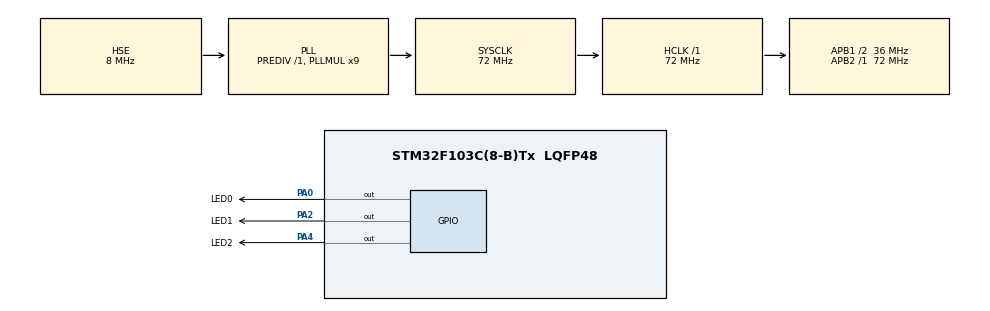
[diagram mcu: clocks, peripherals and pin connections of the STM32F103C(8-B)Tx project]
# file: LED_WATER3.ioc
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Mcu.Family=STM32F1
Mcu.Name=STM32F103C(8-B)Tx
Mcu.Package=LQFP48
NVIC.PriorityGroup=NVIC_PRIORITYGROUP_4
PA0-WKUP.GPIO_Label=LED0
PA0-WKUP.Signal=GPIO_Output
PA13.Mode=Serial_Wire
PA13.Signal=SYS_JTMS-SWDIO
PA14.Mode=Serial_Wire
PA14.Signal=SYS_JTCK-SWCLK
PA2.GPIO_Label=LED1
PA2.Signal=GPIO_Output
PA4.GPIO_Label=LED2
PA4.Signal=GPIO_Output
PD0-OSC_IN.Mode=HSE-External-Oscillator
PD0-OSC_IN.Signal=RCC_OSC_IN
PD1-OSC_OUT.Mode=HSE-External-Oscillator
PD1-OSC_OUT.Signal=RCC_OSC_OUT
ProjectManager.HeapSize=0x200
ProjectManager.StackSize=0x400
ProjectManager.TargetToolchain=STM32CubeIDE
RCC.AHBFreq_Value=72000000
RCC.APB1CLKDivider=RCC_HCLK_DIV2
RCC.APB1Freq_Value=36000000
RCC.APB1TimFreq_Value=72000000
RCC.APB2Freq_Value=72000000
RCC.APB2TimFreq_Value=72000000
RCC.HCLKFreq_Value=72000000
RCC.PLLMUL=RCC_PLL_MUL9
RCC.PLLSourceVirtual=RCC_PLLSOURCE_HSE
RCC.SYSCLKFreq_VALUE=72000000
RCC.SYSCLKSource=RCC_SYSCLKSOURCE_PLLCLK
RCC.USBFreq_Value=72000000
board=custom

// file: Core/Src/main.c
/* USER CODE BEGIN Header */
/**
  ******************************************************************************
  * @file           : main.c
  * @brief          : Main program body
  ******************************************************************************
  * @attention
  *
  * Copyright (c) 2026 STMicroelectronics.
  * All rights reserved.
  *
  * This software is licensed under terms that can be found in the LICENSE file
  * in the root directory of this software component.
  * If no LICENSE file comes with this software, it is provided AS-IS.
  *
  ******************************************************************************
  */
/* USER CODE END Header */
#include "main.h"
#include "gpio.h"

/* USER CODE BEGIN PD */
#define LED_NUM               3U
#define LED_FLOW_INTERVAL_MS  500U
#define LED_LEVEL_ON          GPIO_PIN_SET
#define LED_LEVEL_OFF         GPIO_PIN_RESET
/* USER CODE END PD */

/* USER CODE BEGIN PV */
typedef struct
{
  GPIO_TypeDef *port;
  uint16_t      pin;
} LedDef_t;

static const LedDef_t s_ledTable[LED_NUM] =
{
  { LED0_GPIO_Port, LED0_Pin },
  { LED1_GPIO_Port, LED1_Pin },
  { LED2_GPIO_Port, LED2_Pin },
};

static uint32_t s_lastTick = 0U;
static uint8_t  s_step     = 0U;
/* USER CODE END PV */

void SystemClock_Config(void);
/* USER CODE BEGIN PFP */
static void Led_Write(uint8_t idx, uint8_t on);
static void LedFlow_Init(void);
static void LedFlow_Task(void);
/* USER CODE END PFP */

int main(void)
{

  /* MCU Configuration--------------------------------------------------------*/

  /* Reset of all peripherals, Initializes the Flash interface and the Systick. */
  HAL_Init();

  /* Configure the system clock */
  SystemClock_Config();

  /* Initialize all configured peripherals */
  MX_GPIO_Init();
  /* USER CODE BEGIN 2 */
  LedFlow_Init();
  /* USER CODE END 2 */

  /* Infinite loop */
  while (1)
  {

    /* USER CODE BEGIN 3 */
    LedFlow_Task();
  }
  /* USER CODE END 3 */
}

void SystemClock_Config(void)
{
  RCC_OscInitTypeDef RCC_OscInitStruct = {0};
  RCC_ClkInitTypeDef RCC_ClkInitStruct = {0};

  /** Initializes the RCC Oscillators according to the specified parameters
  * in the RCC_OscInitTypeDef structure.
  */
  RCC_OscInitStruct.OscillatorType = RCC_OSCILLATORTYPE_HSE;
  RCC_OscInitStruct.HSEState = RCC_HSE_ON;
  RCC_OscInitStruct.HSEPredivValue = RCC_HSE_PREDIV_DIV1;
  RCC_OscInitStruct.HSIState = RCC_HSI_ON;
  RCC_OscInitStruct.PLL.PLLState = RCC_PLL_ON;
  RCC_OscInitStruct.PLL.PLLSource = RCC_PLLSOURCE_HSE;
  RCC_OscInitStruct.PLL.PLLMUL = RCC_PLL_MUL9;
  if (HAL_RCC_OscConfig(&RCC_OscInitStruct) != HAL_OK)
  {
    Error_Handler();
  }

  /** Initializes the CPU, AHB and APB buses clocks
  */
  RCC_ClkInitStruct.ClockType = RCC_CLOCKTYPE_HCLK|RCC_CLOCKTYPE_SYSCLK
                              |RCC_CLOCKTYPE_PCLK1|RCC_CLOCKTYPE_PCLK2;
  RCC_ClkInitStruct.SYSCLKSource = RCC_SYSCLKSOURCE_PLLCLK;
  RCC_ClkInitStruct.AHBCLKDivider = RCC_SYSCLK_DIV1;
  RCC_ClkInitStruct.APB1CLKDivider = RCC_HCLK_DIV2;
  RCC_ClkInitStruct.APB2CLKDivider = RCC_HCLK_DIV1;

  if (HAL_RCC_ClockConfig(&RCC_ClkInitStruct, FLASH_LATENCY_2) != HAL_OK)
  {
    Error_Handler();
  }
}

/* USER CODE BEGIN 4 */
static void Led_Write(uint8_t idx, uint8_t on)
{
  GPIO_PinState level = (on != 0U) ? LED_LEVEL_ON : LED_LEVEL_OFF;
  HAL_GPIO_WritePin(s_ledTable[idx].port, s_ledTable[idx].pin, level);
}

static void LedFlow_Init(void)
{
  uint8_t i;

  for (i = 0U; i < LED_NUM; i++)
  {
    Led_Write(i, 0U);
  }

  s_step     = 0U;
  Led_Write(s_step, 1U);
  s_lastTick = HAL_GetTick();
}

static void LedFlow_Task(void)
{
  uint32_t now = HAL_GetTick();

  if ((now - s_lastTick) < LED_FLOW_INTERVAL_MS)
  {
    return;
  }
  s_lastTick = now;

  Led_Write(s_step, 0U);
  s_step = (uint8_t)((s_step + 1U) % LED_NUM);
  Led_Write(s_step, 1U);
}
/* USER CODE END 4 */

void Error_Handler(void)
{
  __disable_irq();
  while (1)
  {
  }
}
